# SIMG301M114KIH register map
Vendor: Silicon Labs; Series: Si; File version: B
Registers are 32-bit, read-write, reset 0x0 unless marked. A register's access mark holds for its fields unless they carry their own. Offsets are from the block's base; [hi:lo] are bit positions; {n}, {i} and the like mark numbered series; 'fields as' and 'values as' point back to an identical list.

## TIMER0_NS — TIMER0_NS Registers
Base 0x40848000
Same registers: TIMER1_NS 0x4084C000, TIMER0_S 0x50848000, TIMER1_S 0x5084C000
0x00 IPVERSION ro reset 0x2
  [31:0] IPVERSION — IP Version ID
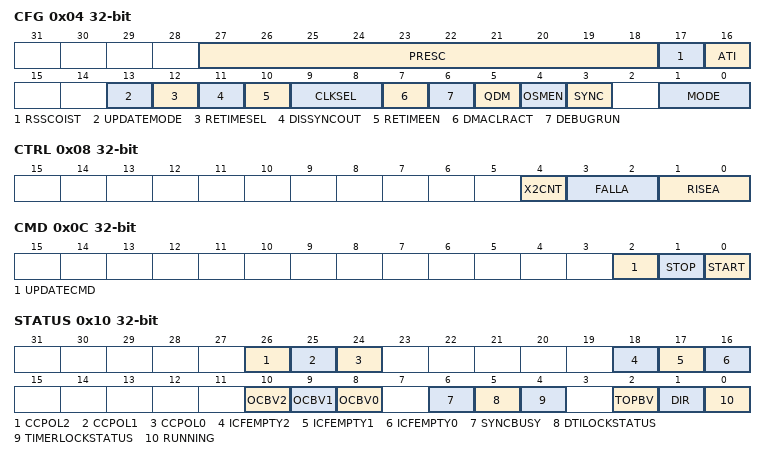
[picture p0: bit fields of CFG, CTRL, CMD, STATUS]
0x04 CFG
  [27:18] PRESC — Prescaler Setting
    0=DIV1 (No prescaling); 1=DIV2 (Prescale by 2); 3=DIV4 (Prescale by 4); 7=DIV8 (Prescale by 8); 15=DIV16 (Prescale by 16); 31=DIV32 (Prescale by 32); 63=DIV64 (Prescale by 64); 127=DIV128 (Prescale by 128); 255=DIV256 (Prescale by 256); 0x1FF=DIV512 (Prescale by 512); 0x3FF=DIV1024 (Prescale by 1024)
  [17] RSSCOIST — Reload-Start Sets COIST
  [16] ATI — Always Track Inputs
  [13] UPDATEMODE — Buffered output update mode
    0=ALL (Direct registers are updated from buffer on every applicable update event.); 1=CMD (Direct registers are updated from buffer on the first applicable update event after CMD.UPDATECMD is set.)
  [12] RETIMESEL — PWM output retime select
  [11] DISSYNCOUT — Disable Timer Start/Stop/Reload output
    0=EN (Timer can start/stop/reload other timers with SYNC bit set); 1=DIS (Timer cannot start/stop/reload other timers with SYNC bit set)
  [10] RETIMEEN — PWM output retimed enable
    0=DISABLE (PWM outputs are not re-timed.); 1=ENABLE (PWM outputs are re-timed.)
  [9:8] CLKSEL — Clock Source Select
    0=PRESCEM01GRPACLK (Prescaled EM01GRPACLK); 1=CC1 (Compare/Capture Channel 1 Input); 2=TIMEROUF (Timer is clocked by underflow(down-count) or overflow(up-count) in the lower numbered neighbor Timer)
  [7] DMACLRACT — DMA Request Clear on Active
  [6] DEBUGRUN — Debug Mode Run Enable
    0=HALT (Timer is halted in debug mode); 1=RUN (Timer is running in debug mode)
  [5] QDM — Quadrature Decoder Mode Selection
    0=X2 (X2 mode selected); 1=X4 (X4 mode selected)
  [4] OSMEN — One-shot Mode Enable
  [3] SYNC — Timer Start/Stop/Reload Synchronization
    0=DISABLE (Timer operation is unaffected by other timers.); 1=ENABLE (Timer may be started, stopped and re-loaded from other timer instances.)
  [1:0] MODE — Timer Mode
    0=UP (Up-count mode); 1=DOWN (Down-count mode); 2=UPDOWN (Up/down-count mode); 3=QDEC (Quadrature decoder mode)
0x08 CTRL
  [4] X2CNT — 2x Count Mode
  [3:2] FALLA — Timer Falling Input Edge Action
    0=NONE (No action); 1=START (Start counter without reload); 2=STOP (Stop counter without reload); 3=RELOADSTART (Reload and start counter)
  [1:0] RISEA — Timer Rising Input Edge Action
    values as FALLA
0x0C CMD wo
  [2] UPDATECMD — Buffered output update
  [1] STOP — Stop Timer
  [0] START — Start Timer
0x10 STATUS ro
  [26] CCPOL2 — Compare/Capture Polarity
    0=LOWRISE (CCx polarity low level/rising edge); 1=HIGHFALL (CCx polarity high level/falling edge)
  [25] CCPOL1 — Compare/Capture Polarity
    values as CCPOL2
  [24] CCPOL0 — Compare/Capture Polarity
    values as CCPOL2
  [18] ICFEMPTY2 — Input capture fifo empty
  [17] ICFEMPTY1 — Input capture fifo empty
  [16] ICFEMPTY0 — Input capture fifo empty
  [10] OCBV2 — Output Compare Buffer Valid
  [9] OCBV1 — Output Compare Buffer Valid
  [8] OCBV0 — Output Compare Buffer Valid
  [6] SYNCBUSY
  [5] DTILOCKSTATUS
    0=UNLOCKED (DTI registers are unlocked); 1=LOCKED (DTI registers are locked)
  [4] TIMERLOCKSTATUS
    0=UNLOCKED (TIMER registers are unlocked); 1=LOCKED (TIMER registers are locked)
  [2] TOPBV — TOP Buffer Valid
  [1] DIR — Direction
    0=UP (Counting up); 1=DOWN (Counting down)
  [0] RUNNING
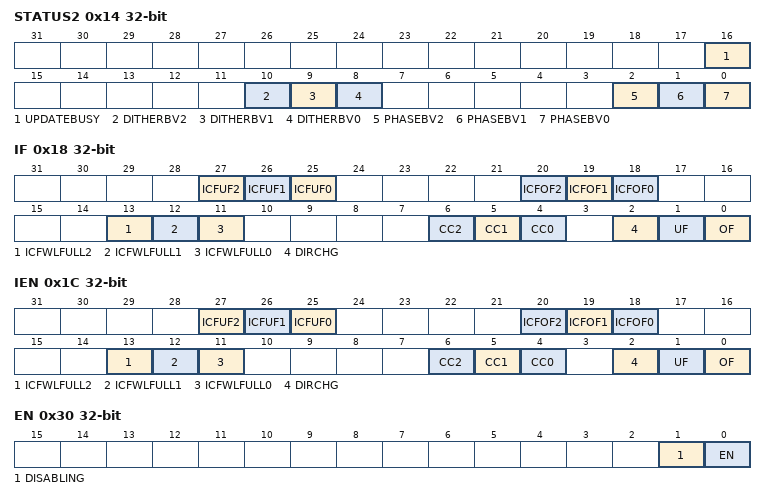
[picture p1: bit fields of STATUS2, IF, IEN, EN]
0x14 STATUS2 ro
  [16] UPDATEBUSY — Buffer output update busy
  [10] DITHERBV2 — Dither valid buffer
  [9] DITHERBV1 — Dither valid buffer
  [8] DITHERBV0 — Dither valid buffer
  [2] PHASEBV2 — Phase valid buffer
  [1] PHASEBV1 — Phase valid buffer
  [0] PHASEBV0 — Phase valid buffer
0x18 IF
  [27] ICFUF2 — Input capture FIFO underflow
  [26] ICFUF1 — Input capture FIFO underflow
  [25] ICFUF0 — Input capture FIFO underflow
  [20] ICFOF2 — Input Capture FIFO overflow
  [19] ICFOF1 — Input Capture FIFO overflow
  [18] ICFOF0 — Input Capture FIFO overflow
  [13] ICFWLFULL2 — Input Capture Watermark Level Full
  [12] ICFWLFULL1 — Input Capture Watermark Level Full
  [11] ICFWLFULL0 — Input Capture Watermark Level Full
  [6] CC2 — Capture Compare Channel 2 Interrupt Flag
  [5] CC1 — Capture Compare Channel 1 Interrupt Flag
  [4] CC0 — Capture Compare Channel 0 Interrupt Flag
  [2] DIRCHG — Direction Change Detect Interrupt Flag
  [1] UF — Underflow Interrupt Flag
  [0] OF — Overflow Interrupt Flag
0x1C IEN
  [27] ICFUF2 — ICFUF2 Interrupt Enable
  [26] ICFUF1 — ICFUF1 Interrupt Enable
  [25] ICFUF0 — ICFUF0 Interrupt Enable
  [20] ICFOF2 — ICFOF2 Interrupt Enable
  [19] ICFOF1 — ICFOF1 Interrupt Enable
  [18] ICFOF0 — ICFOF0 Interrupt Enable
  [13] ICFWLFULL2 — ICFWLFULL2 Interrupt Enable
  [12] ICFWLFULL1 — ICFWLFULL1 Interrupt Enable
  [11] ICFWLFULL0 — ICFWLFULL0 Interrupt Enable
  [6] CC2 — CC2 Interrupt Enable
  [5] CC1 — CC1 Interrupt Enable
  [4] CC0 — CC0 Interrupt Enable
  [2] DIRCHG — Direction Change Detect Interrupt Enable
  [1] UF — Underflow Interrupt Enable
  [0] OF — Overflow Interrupt Enable
0x20 TOP reset 0xFFFF
  [31:0] TOP — Counter Top Value
0x24 TOPB
  [31:0] TOPB — Counter Top Buffer Register
0x28 CNT
  [31:0] CNT — Counter Value
0x2C LOCK wo
  [15:0] LOCKKEY — Timer Lock Key
    0xCE80=UNLOCK (Write to unlock TIMER registers)
0x30 EN
  [1] DISABLING ro — Disablement busy status
  [0] EN — Timer Module Enable
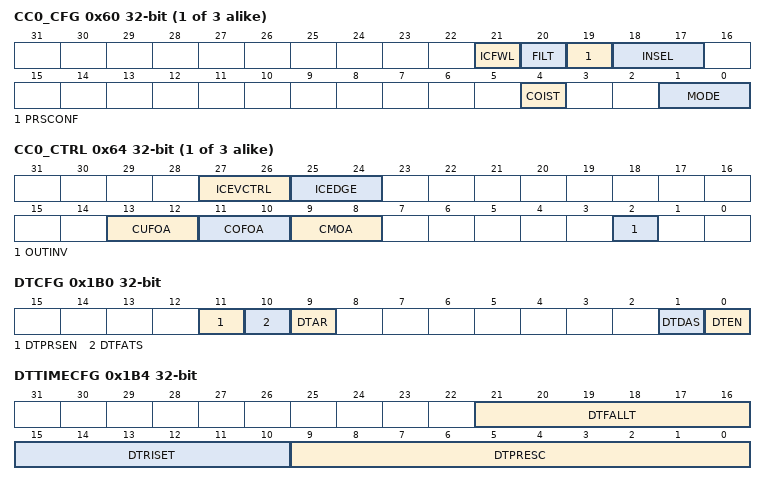
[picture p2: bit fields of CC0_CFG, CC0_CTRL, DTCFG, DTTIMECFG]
{0x60+0x30*i} CC{i}_CFG (i=0..2)
  [21] ICFWL — Input Capture FIFO watermark level
  [20] FILT — Digital Filter
    0=DISABLE (Digital Filter Disabled); 1=ENABLE (Digital Filter Enabled)
  [19] PRSCONF — PRS Configuration
    0=PULSE (Each CC event will generate a one EM01GRPACLK cycle high pulse); 1=LEVEL (The PRS channel will follow CC out)
  [18:17] INSEL — Input Selection
    0=PIN (TIMERnCCx pin is selected); 1=PRSSYNC (Synchornous PRS selected); 2=PRSASYNCLEVEL (Asynchronous Level PRS selected); 3=PRSASYNCPULSE (Asynchronous Pulse PRS selected)
  [4] COIST — Compare Output Initial State
  [1:0] MODE — CC Channel Mode
    0=OFF (Compare/Capture channel turned off); 1=INPUTCAPTURE; 2=OUTPUTCOMPARE; 3=PWM (Pulse-Width Modulation)
{0x64+0x30*i} CC{i}_CTRL (i=0..2)
  [27:26] ICEVCTRL — Input Capture Event Control
    0=EVERYEDGE (PRS output pulse and interrupt flag set on every capture); 1=EVERYSECONDEDGE (PRS output pulse and interrupt flag set on every second capture); 2=RISING (PRS output pulse and interrupt flag set on rising edge only (if ICEDGE = BOTH)); 3=FALLING (PRS output pulse and interrupt flag set on falling edge only (if ICEDGE = BOTH))
  [25:24] ICEDGE — Input Capture Edge Select
    0=RISING (Rising edges detected); 1=FALLING (Falling edges detected); 2=BOTH (Both edges detected); 3=NONE (No edge detection, signal is left as it is)
  [13:12] CUFOA — Counter Underflow Output Action
    0=NONE (No action on counter underflow); 1=TOGGLE (Toggle output on counter underflow); 2=CLEAR (Clear output on counter underflow); 3=SET (Set output on counter underflow)
  [11:10] COFOA — Counter Overflow Output Action
    0=NONE (No action on counter overflow); 1=TOGGLE (Toggle output on counter overflow); 2=CLEAR (Clear output on counter overflow); 3=SET (Set output on counter overflow)
  [9:8] CMOA — Compare Match Output Action
    0=NONE (No action on compare match); 1=TOGGLE (Toggle output on compare match); 2=CLEAR (Clear output on compare match); 3=SET (Set output on compare match)
  [2] OUTINV — Output Invert
{0x68+0x30*i} CC{i}_PHASE (i=0..2)
  [31:0] PHASE — Phase Value of CC
{0x6C+0x30*i} CC{i}_PHASEB (i=0..2)
  [31:0] PHASEB — Phase Value Buffer
{0x70+0x30*i} CC{i}_OC (i=0..2)
  [31:0] OC — Output Compare Value
{0x74+0x30*i} CC{i}_OCB (i=0..2)
  [31:0] OCB — Output Compare Value Buffer
{0x78+0x30*i} CC{i}_DITHER (i=0..2)
  [3:0] DITHER — Dither Value
{0x7C+0x30*i} CC{i}_DITHERB (i=0..2)
  [3:0] DITHERB — Dither Value Buffer
{0x84+0x30*i} CC{i}_ICF ro (i=0..2)
  [31:0] ICF — Input Capture FIFO
{0x88+0x30*i} CC{i}_ICOF ro (i=0..2)
  [31:0] ICOF — Input Capture FIFO Overflow
0x1B0 DTCFG
  [11] DTPRSEN — DTI PRS Source Enable
  [10] DTFATS — DTI Fault Action on Timer Stop
  [9] DTAR — DTI Always Run
  [1] DTDAS — DTI Automatic Start-up Functionality
    0=NORESTART (No DTI restart on debugger exit); 1=RESTART (DTI restart on debugger exit)
  [0] DTEN — DTI Enable
0x1B4 DTTIMECFG
  [21:16] DTFALLT — DTI Fall-time
  [15:10] DTRISET — DTI Rise-time
  [9:0] DTPRESC — DTI Prescaler Setting
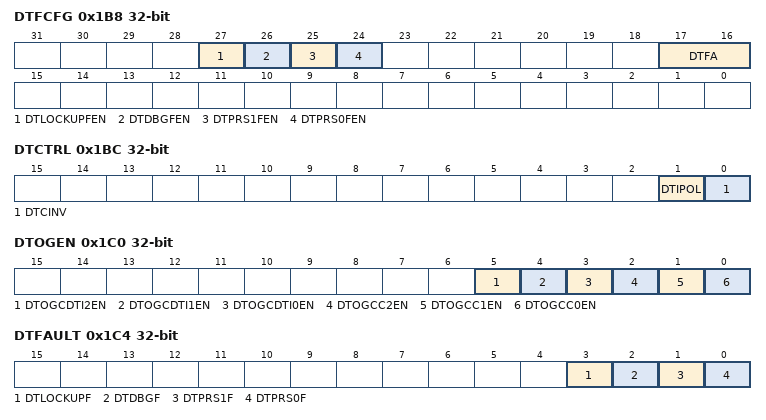
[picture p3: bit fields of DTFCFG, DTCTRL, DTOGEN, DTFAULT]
0x1B8 DTFCFG
  [27] DTLOCKUPFEN — DTI Lockup Fault Enable
  [26] DTDBGFEN — DTI Debugger Fault Enable
  [25] DTPRS1FEN — DTI PRS 1 Fault Enable
  [24] DTPRS0FEN — DTI PRS 0 Fault Enable
  [17:16] DTFA — DTI Fault Action
    0=NONE (No action on fault); 1=INACTIVE (Set outputs inactive); 2=CLEAR (Clear outputs); 3=TRISTATE (Tristate outputs)
0x1BC DTCTRL
  [1] DTIPOL — DTI Inactive Polarity
  [0] DTCINV — DTI Complementary Output Invert.
0x1C0 DTOGEN
  [5] DTOGCDTI2EN — DTI CDTIn Output Generation Enable
  [4] DTOGCDTI1EN — DTI CDTIn Output Generation Enable
  [3] DTOGCDTI0EN — DTI CDTIn Output Generation Enable
  [2] DTOGCC2EN — DTI CCn Output Generation Enable
  [1] DTOGCC1EN — DTI CCn Output Generation Enable
  [0] DTOGCC0EN — DTI CCn Output Generation Enable
0x1C4 DTFAULT ro
  [3] DTLOCKUPF — DTI Lockup Fault
  [2] DTDBGF — DTI Debugger Fault
  [1] DTPRS1F — DTI PRS 1 Fault
  [0] DTPRS0F — DTI PRS 0 Fault
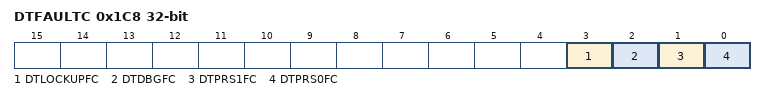
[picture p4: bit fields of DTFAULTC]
0x1C8 DTFAULTC wo
  [3] DTLOCKUPFC — DTI Lockup Fault Clear
  [2] DTDBGFC — DTI Debugger Fault Clear
  [1] DTPRS1FC — DTI PRS1 Fault Clear
  [0] DTPRS0FC — DTI PRS0 Fault Clear
0x1CC DTLOCK wo
  [15:0] DTILOCKKEY
    0xCE80=UNLOCK (Write to unlock TIMER DTI registers)

## TIMER2_NS — TIMER2_NS Registers
Base 0x40850000
Same registers: TIMER3_NS 0x40854000, TIMER2_S 0x50850000, TIMER3_S 0x50854000
Registers as TIMER0_NS; these are added or differ:
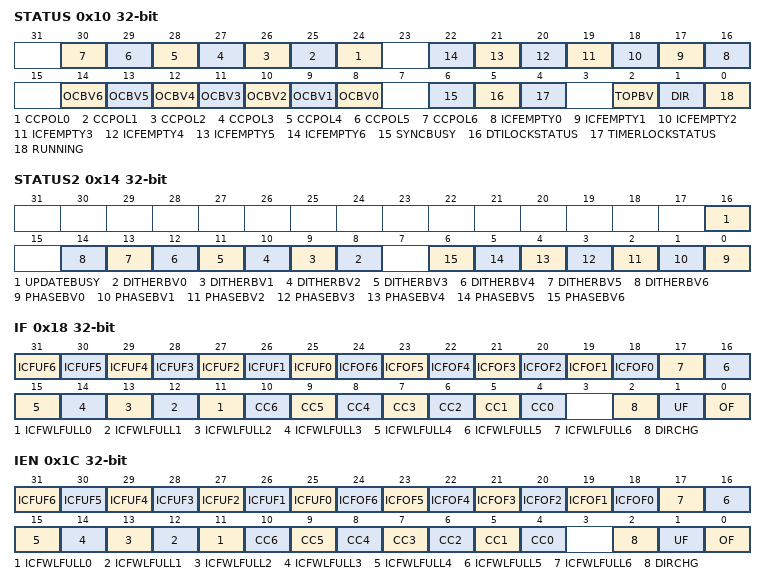
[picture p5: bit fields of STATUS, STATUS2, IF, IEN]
0x10 STATUS ro
  [n+24] CCPOL{n} (n=0..6) — Compare/Capture Polarity
    0=LOWRISE (CCx polarity low level/rising edge); 1=HIGHFALL (CCx polarity high level/falling edge)
  [n+16] ICFEMPTY{n} (n=0..6) — Input capture fifo empty
  [n+8] OCBV{n} (n=0..6) — Output Compare Buffer Valid
  [6] SYNCBUSY
  [5] DTILOCKSTATUS
    0=UNLOCKED (DTI registers are unlocked); 1=LOCKED (DTI registers are locked)
  [4] TIMERLOCKSTATUS
    0=UNLOCKED (TIMER registers are unlocked); 1=LOCKED (TIMER registers are locked)
  [2] TOPBV — TOP Buffer Valid
  [1] DIR — Direction
    0=UP (Counting up); 1=DOWN (Counting down)
  [0] RUNNING
0x14 STATUS2 ro
  [16] UPDATEBUSY — Buffer output update busy
  [n+8] DITHERBV{n} (n=0..6) — Dither valid buffer
  [n] PHASEBV{n} (n=0..6) — Phase valid buffer
0x18 IF
  [n+25] ICFUF{n} (n=0..6) — Input capture FIFO underflow
  [n+18] ICFOF{n} (n=0..6) — Input Capture FIFO overflow
  [n+11] ICFWLFULL{n} (n=0..6) — Input Capture Watermark Level Full
  [n+4] CC{n} (n=0..6) — Capture Compare Channel {n} Interrupt Flag
  [2] DIRCHG — Direction Change Detect Interrupt Flag
  [1] UF — Underflow Interrupt Flag
  [0] OF — Overflow Interrupt Flag
0x1C IEN
  [n+25] ICFUF{n} (n=0..6) — ICFUF{n} Interrupt Enable
  [n+18] ICFOF{n} (n=0..6) — ICFOF{n} Interrupt Enable
  [n+11] ICFWLFULL{n} (n=0..6) — ICFWLFULL{n} Interrupt Enable
  [n+4] CC{n} (n=0..6) — CC{n} Interrupt Enable
  [2] DIRCHG — Direction Change Detect Interrupt Enable
  [1] UF — Underflow Interrupt Enable
  [0] OF — Overflow Interrupt Enable
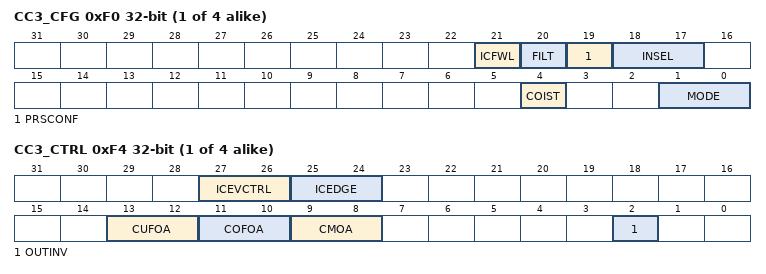
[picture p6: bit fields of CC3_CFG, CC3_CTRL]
{0x60+0x30*i} CC{i}_CFG (i=3..6)
  fields as TIMER0_NS.CC0_CFG
{0x64+0x30*i} CC{i}_CTRL (i=3..6)
  fields as TIMER0_NS.CC0_CTRL
{0x68+0x30*i} CC{i}_PHASE (i=3..6)
  [31:0] PHASE — Phase Value of CC
{0x6C+0x30*i} CC{i}_PHASEB (i=3..6)
  [31:0] PHASEB — Phase Value Buffer
{0x70+0x30*i} CC{i}_OC (i=3..6)
  [31:0] OC — Output Compare Value
{0x74+0x30*i} CC{i}_OCB (i=3..6)
  [31:0] OCB — Output Compare Value Buffer
{0x78+0x30*i} CC{i}_DITHER (i=3..6)
  [3:0] DITHER — Dither Value
{0x7C+0x30*i} CC{i}_DITHERB (i=3..6)
  [3:0] DITHERB — Dither Value Buffer
{0x84+0x30*i} CC{i}_ICF ro (i=3..6)
  [31:0] ICF — Input Capture FIFO
{0x88+0x30*i} CC{i}_ICOF ro (i=3..6)
  [31:0] ICOF — Input Capture FIFO Overflow
